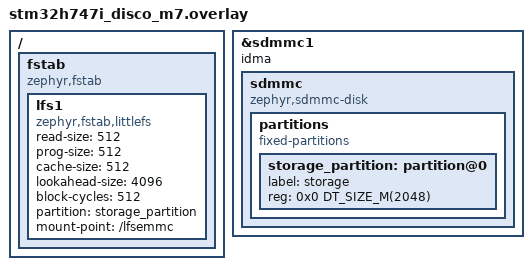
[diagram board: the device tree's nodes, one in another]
/*
 * Copyright (c) 2022 Christoph Heller
 *
 * SPDX-License-Identifier: Apache-2.0
 */

/delete-node/ &storage_partition;

/ {
	fstab {
		compatible = "zephyr,fstab";
		lfs1: lfs1 {
			compatible = "zephyr,fstab,littlefs";
			read-size = <512>;
			prog-size = <512>;
			cache-size = <512>;
			lookahead-size = <4096>;
			block-cycles = <512>;
			partition = <&storage_partition>;
			mount-point = "/lfsemmc";
		};
	};
};

&sdmmc1 {
        idma;
        sdmmc {
		compatible = "zephyr,sdmmc-disk";
		status = "okay";
		partitions {
			compatible = "fixed-partitions";
			#address-cells = <1>;
			#size-cells = <1>;
			storage_partition: partition@0 {
				label = "storage";
				reg = <0x0 DT_SIZE_M(2048)>;
			};
		};
	};
};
